# PIC32CZ2038CA70100 register map
Vendor: Microchip Technology; Series: CA70; File version: 0
Microchip PIC32CZ2038CA70100 Microcontroller
CPU: CM7 r1p1, little endian, MPU, FPU, 3 interrupt priority bits
Registers are 32-bit, access not given, no defined reset value unless marked. A register's access mark holds for its fields unless they carry their own. Offsets are from the block's base; lines under a group give offsets from that group; [hi:lo] are bit positions; {n}, {i} and the like mark numbered series; 'fields as' and 'values as' point back to an identical list; <NAME> marks a mode.

## Memory map
0x00000000 LOCKBIT size 0x10
0x40000000 HSMCI size 0xB58 — High Speed MultiMedia Card Interface
0x40004000 SSC size 0xEC — Synchronous Serial Controller
0x40008000 SPI0 size 0xEC — Serial Peripheral Interface
0x4000C000 TC0 size 0xE8 — Timer Counter
0x40010000 TC1 size 0xE8
0x40014000 TC2 size 0xE8
0x40018000 TWI0 size 0xEC — Two-wire Interface
0x4001C000 TWI1 size 0xEC
0x40020000 PWMC0 size 0x464 — Pulse Width Modulation Controller
0x40024000 USART0 size 0xEC — Universal Synchronous Asynchronous Receiver Transmitter
0x40028000 USART1 size 0xEC
0x4002C000 USART2 size 0xEC
0x40030000 MCAN0 size 0xFC — Controller Area Network
0x40034000 MCAN1 size 0xFC
0x40038000 USBHS size 0x830 — USB High-Speed Interface
0x4003C000 AFEC0 size 0xEC — Analog Front-End Controller
0x40044000 ACC size 0xEC — Analog Comparator Controller
0x40048000 ICM size 0x58 — Integrity Check Monitor
0x4004C000 ISI size 0xEC — Image Sensor Interface
0x40050000 GMAC size 0x7C0 — Gigabit Ethernet MAC
0x40054000 TC3 size 0xE8
0x40058000 SPI1 size 0xEC
0x4005C000 PWMC1 size 0x464
0x40060000 TWI2 size 0xEC
0x40064000 AFEC1 size 0xEC
0x40068000 MLB size 0x3E0 — MediaLB
0x4006C000 AES size 0xAC — Advanced Encryption Standard
0x40070000 TRNG size 0x54 — True Random Number Generator
0x40078000 XDMAC size 0xE60 — Extensible DMA Controller
0x4007C000 QSPI size 0xEC — Quad Serial Peripheral Interface
0x40088000 MATRIX size 0x1EC — AHB Bus Matrix
0x4008C000 I2SC0 size 0x28 — Inter-IC Sound Controller
0x40090000 I2SC1 size 0x28
0x400E0400 UTMI size 0x34 — USB Transmitter Interface Macrocell
0x400E0600 PMC size 0x160 — Power Management Controller
0x400E0800 UART0 size 0xE8 — Universal Asynchronous Receiver Transmitter
0x400E0940 CHIPID size 0x8 — Chip Identifier
0x400E0A00 UART1 size 0xE8
0x400E0C00 EFC size 0xE8 — Embedded Flash Controller
0x400E0E00 PORTA size 0x168 — Port
0x400E1000 PORTB size 0x168
0x400E1400 PORTD size 0x168
0x400E1800 RSTC size 0xC — Reset Controller
0x400E1810 SUPC size 0x18 — Supply Controller
0x400E1830 RTT size 0x10 — Real-time Timer
0x400E1850 WDT size 0xC — Watchdog Timer
0x400E1860 RTC size 0x30 — Real-time Clock
0x400E1890 GPBR size 0x20 — General Purpose Backup Registers
0x400E1900 RSWDT size 0xC — Reinforced Safety Watchdog Timer
0x400E1A00 UART2 size 0xE8
0x400E1C00 UART3 size 0xE8
0x400E1E00 UART4 size 0xE8
0xE000E000 SystemControl size 0xD8C — System Control Registers
0xE000E010 SysTick size 0x10 — System timer
0xE000E100 NVIC size 0xE04 — Nested Vectored Interrupt Controller
0xE000ED90 MPU size 0x14 — Memory Protection Unit Registers
0xE000EF34 FPU size 0xC — Floating Point Unit Registers

## Interrupts
0 SUPC
1 RSTC
2 RTC
3 RTT
4 WDT
5 PMC
6 EFC
7 UART0
8 UART1
10 PORTA
11 PORTB
13 USART0
14 USART1
15 USART2
16 PORTD
18 HSMCI
19 TWI0
20 TWI1
21 SPI0
22 SSC
23 TC0_CH0 (TC0)
24 TC0_CH1 (TC0)
25 TC0_CH2 (TC0)
26 TC1_CH0 (TC1)
27 TC1_CH1 (TC1)
28 TC1_CH2 (TC1)
29 AFEC0
31 PWMC0
32 ICM
33 ACC
34 USBHS
35 MCAN0
37 MCAN1
39 GMAC
40 AFEC1
41 TWI2
42 SPI1
43 QSPI
44 UART2
45 UART3
46 UART4
47 TC2_CH0 (TC2)
48 TC2_CH1 (TC2)
49 TC2_CH2 (TC2)
50 TC3_CH0 (TC3)
51 TC3_CH1 (TC3)
52 TC3_CH2 (TC3)
53 MLB
56 AES
57 TRNG
58 XDMAC
59 ISI
60 PWMC1
63 RSWDT
69 I2SC0
70 I2SC1

## ACC — Analog Comparator Controller
Base 0x40044000; register names take the prefix ACC_
0x00 ACC_CR wo — Control Register
  [0] SWRST — Software Reset
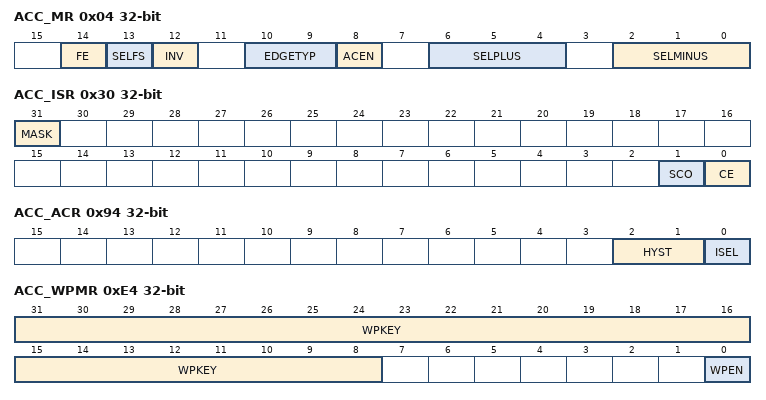
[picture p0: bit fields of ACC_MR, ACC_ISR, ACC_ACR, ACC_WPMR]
0x04 ACC_MR — Mode Register
  [14] FE — Fault Enable
    0=DIS (The FAULT output is tied to 0.); 1=EN (The FAULT output is driven by the signal defined by SELFS.)
  [13] SELFS — Selection Of Fault Source
    0=CE (The CE flag is used to drive the FAULT output.); 1=OUTPUT (The output of the analog comparator flag is used to drive the FAULT output.)
  [12] INV — Invert Comparator Output
    0=DIS (Analog comparator output is directly processed.); 1=EN (Analog comparator output is inverted prior to being processed.)
  [10:9] EDGETYP — Edge Type
    0=RISING (Only rising edge of comparator output); 1=FALLING (Falling edge of comparator output); 2=ANY (Any edge of comparator output)
  [8] ACEN — Analog Comparator Enable
    0=DIS (Analog comparator disabled.); 1=EN (Analog comparator enabled.)
  [6:4] SELPLUS — Selection For Plus Comparator Input
    {v}=AFE0_AD{v} (Select AFE0_AD{v}) (v=0..5); 6=AFE1_AD0 (Select AFE1_AD0); 7=AFE1_AD1 (Select AFE1_AD1)
  [2:0] SELMINUS — Selection for Minus Comparator Input
    0=TS (Select TS); 1=VREFP (Select VREFP); 2=DAC0 (Select DAC0); 3=DAC1 (Select DAC1); {v}=AFE0_AD{v-4} (Select AFE0_AD{v-4}) (v=4..7)
0x24 ACC_IER wo — Interrupt Enable Register
  [0] CE — Comparison Edge
0x28 ACC_IDR wo — Interrupt Disable Register
  [0] CE — Comparison Edge
0x2C ACC_IMR ro — Interrupt Mask Register
  [0] CE — Comparison Edge
0x30 ACC_ISR ro — Interrupt Status Register
  [31] MASK — Flag Mask
  [1] SCO — Synchronized Comparator Output
  [0] CE — Comparison Edge (cleared on read)
0x94 ACC_ACR — Analog Control Register
  [2:1] HYST — Hysteresis Selection
  [0] ISEL — Current Selection
    0=LOPW (Low-power option.); 1=HISP (High-speed option.)
0xE4 ACC_WPMR — Write Protection Mode Register
  [31:8] WPKEY — Write Protection Key
    0x414343=PASSWD (Writing any other value in this field aborts the write operation of the WPEN bit.Always reads as 0.)
  [0] WPEN — Write Protection Enable
0xE8 ACC_WPSR ro — Write Protection Status Register
  [0] WPVS — Write Protection Violation Status

## Notices in the file
Copyright (c) 2017 Microchip Technology Inc.
SPDX-License-Identifier: Apache-2.0
Licensed under the Apache License, Version 2.0 (the "License");
you may not use this file except in compliance with the License.
You may obtain a copy of the License at
http://www.apache.org/licenses/LICENSE-2.0
Unless required by applicable law or agreed to in writing, software
distributed under the License is distributed on an "AS IS" BASIS,
WITHOUT WARRANTIES OR CONDITIONS OF ANY KIND, either express or implied.
See the License for the specific language governing permissions and
limitations under the License.
